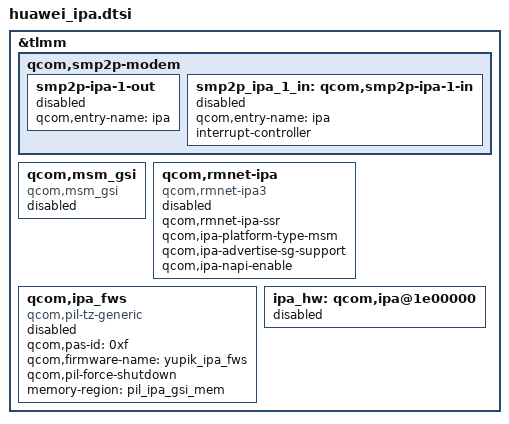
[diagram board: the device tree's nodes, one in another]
&tlmm{
	qcom,smp2p-modem {
		smp2p-ipa-1-out {
			qcom,entry-name = "ipa";
			#qcom,smem-state-cells = <1>;
			status = "disabled";
		};

		/* ipa - inbound entry from mss */
		smp2p_ipa_1_in: qcom,smp2p-ipa-1-in {
			qcom,entry-name = "ipa";
			interrupt-controller;
			#interrupt-cells = <2>;
			status = "disabled";
		};
		/* Nedd add for ipa end*/
	};
	/* Need add for ipa*/
	qcom,msm_gsi {
		compatible = "qcom,msm_gsi";
		status = "disabled";
	};

	qcom,rmnet-ipa {
		compatible = "qcom,rmnet-ipa3";
		qcom,rmnet-ipa-ssr;
		qcom,ipa-platform-type-msm;
		qcom,ipa-advertise-sg-support;
		qcom,ipa-napi-enable;
		status = "disabled";
	};

	qcom,ipa_fws {
		compatible = "qcom,pil-tz-generic";
		qcom,pas-id = <0xf>;
		qcom,firmware-name = "yupik_ipa_fws";
		qcom,pil-force-shutdown;
		memory-region = <&pil_ipa_gsi_mem>;
		status = "disabled";
	};
	/* Need add for ipa end*/

	ipa_hw: qcom,ipa@1e00000 {

		/* Need add for ipa start*/
		status = "disabled";
		/* Need add for ipa end*/

	};
};
